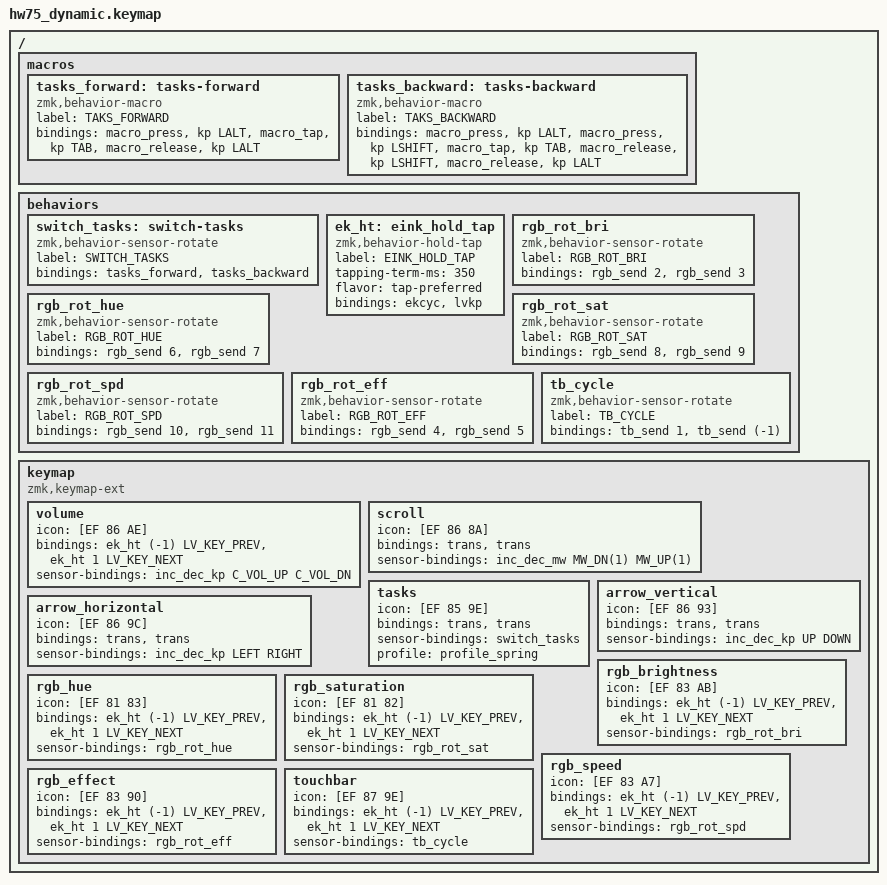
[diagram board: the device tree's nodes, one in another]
/*
 * Copyright (c) 2022 The ZMK Contributors
 * SPDX-License-Identifier: MIT
 */

#include <behaviors.dtsi>
#include <behaviors/lvgl_key_press.dtsi>
#include <behaviors/sensor_rotate_mouse_wheel.dtsi>
#include <behaviors/eink_mode_cycle.dtsi>
#include <behaviors/rgb_send.dtsi>
#include <behaviors/tb_send.dtsi>
#include <dt-bindings/zmk/keys.h>
#include <dt-bindings/zmk/rgb.h>
#include <dt-bindings/zmk/lvgl.h>
#include <dt-bindings/zmk/mouse.h>

/ {
	macros {
		tasks_forward: tasks-forward {
			label = "TAKS_FORWARD";
			compatible = "zmk,behavior-macro";
			#binding-cells = <0>;
			bindings = <&macro_press   &kp LALT>,
				   <&macro_tap     &kp TAB>,
				   <&macro_release &kp LALT>;
		};

		tasks_backward: tasks-backward {
			label = "TAKS_BACKWARD";
			compatible = "zmk,behavior-macro";
			#binding-cells = <0>;
			bindings = <&macro_press   &kp LALT>,
				   <&macro_press   &kp LSHIFT>,
				   <&macro_tap     &kp TAB>,
				   <&macro_release &kp LSHIFT>,
				   <&macro_release &kp LALT>;
		};
	};

	behaviors {
		switch_tasks: switch-tasks {
			compatible = "zmk,behavior-sensor-rotate";
			label = "SWITCH_TASKS";
			#sensor-binding-cells = <0>;
			bindings = <&tasks_forward>, <&tasks_backward>;
		};

		/*
		 * Short press -> LVGL keypad event (existing screen navigation).
		 * Long press  -> cycle E-Ink mode forward/backward.
		 * The two keymap cells are: <cycle-delta> <lvgl-key>.
		 */
		ek_ht: eink_hold_tap {
			compatible = "zmk,behavior-hold-tap";
			label = "EINK_HOLD_TAP";
			#binding-cells = <2>;
			tapping-term-ms = <350>;
			flavor = "tap-preferred";
			bindings = <&ekcyc>, <&lvkp>;
		};

		/*
		 * Knob -> keyboard underglow over D2K. Each rotate step sends one
		 * relative ±1 opcode (see uart_comm.proto RgbCmd). The keyboard is
		 * stateless; all the UI lives here on the dynamic module.
		 */
		rgb_rot_bri: rgb_rot_bri {
			compatible = "zmk,behavior-sensor-rotate";
			label = "RGB_ROT_BRI";
			#sensor-binding-cells = <0>;
			bindings = <&rgb_send 2>, <&rgb_send 3>;
		};
		rgb_rot_hue: rgb_rot_hue {
			compatible = "zmk,behavior-sensor-rotate";
			label = "RGB_ROT_HUE";
			#sensor-binding-cells = <0>;
			bindings = <&rgb_send 6>, <&rgb_send 7>;
		};
		rgb_rot_sat: rgb_rot_sat {
			compatible = "zmk,behavior-sensor-rotate";
			label = "RGB_ROT_SAT";
			#sensor-binding-cells = <0>;
			bindings = <&rgb_send 8>, <&rgb_send 9>;
		};
		rgb_rot_spd: rgb_rot_spd {
			compatible = "zmk,behavior-sensor-rotate";
			label = "RGB_ROT_SPD";
			#sensor-binding-cells = <0>;
			bindings = <&rgb_send 10>, <&rgb_send 11>;
		};
		rgb_rot_eff: rgb_rot_eff {
			compatible = "zmk,behavior-sensor-rotate";
			label = "RGB_ROT_EFF";
			#sensor-binding-cells = <0>;
			bindings = <&rgb_send 4>, <&rgb_send 5>;
		};

		/* Knob cycles the keyboard TouchBar mode (PAN/APP/DESKTOP) over D2K. */
		tb_cycle: tb_cycle {
			compatible = "zmk,behavior-sensor-rotate";
			label = "TB_CYCLE";
			#sensor-binding-cells = <0>;
			bindings = <&tb_send 1>, <&tb_send (-1)>;
		};
	};

	keymap {
		compatible = "zmk,keymap-ext", "zmk,keymap";

		volume {
			label = "音量";
			icon = [EF 86 AE];
			bindings = <&ek_ht (-1) LV_KEY_PREV &ek_ht 1 LV_KEY_NEXT>;
			sensor-bindings = <&inc_dec_kp C_VOL_UP C_VOL_DN>;
		};

		scroll {
			label = "滚动";
			icon = [EF 86 8A];
			bindings = <&trans &trans>;
			sensor-bindings = <&inc_dec_mw MW_DN(1) MW_UP(1)>;
		};

		tasks {
			label = "窗口";
			icon = [EF 85 9E];
			bindings = <&trans &trans>;
			sensor-bindings = <&switch_tasks>;
			profile = <&profile_spring>;
		};

		arrow_vertical {
			label = "上下";
			icon = [EF 86 93];
			bindings = <&trans &trans>;
			sensor-bindings = <&inc_dec_kp UP DOWN>;
		};

		arrow_horizontal {
			label = "左右";
			icon = [EF 86 9C];
			bindings = <&trans &trans>;
			sensor-bindings = <&inc_dec_kp LEFT RIGHT>;
		};

		/*
		 * On-device keyboard-RGB control. Knob rotation adjusts the parameter;
		 * the two keys navigate the carousel (short) / cycle E-Ink mode (long),
		 * same as the other layers. No PC needed.
		 */
		rgb_brightness {
			label = "亮度";
			icon = [EF 83 AB];
			bindings = <&ek_ht (-1) LV_KEY_PREV &ek_ht 1 LV_KEY_NEXT>;
			sensor-bindings = <&rgb_rot_bri>;
		};

		rgb_hue {
			label = "色相";
			icon = [EF 81 83];
			bindings = <&ek_ht (-1) LV_KEY_PREV &ek_ht 1 LV_KEY_NEXT>;
			sensor-bindings = <&rgb_rot_hue>;
		};

		rgb_saturation {
			label = "饱和";
			icon = [EF 81 82];
			bindings = <&ek_ht (-1) LV_KEY_PREV &ek_ht 1 LV_KEY_NEXT>;
			sensor-bindings = <&rgb_rot_sat>;
		};

		rgb_speed {
			label = "速度";
			icon = [EF 83 A7];
			bindings = <&ek_ht (-1) LV_KEY_PREV &ek_ht 1 LV_KEY_NEXT>;
			sensor-bindings = <&rgb_rot_spd>;
		};

		rgb_effect {
			label = "效果";
			icon = [EF 83 90];
			bindings = <&ek_ht (-1) LV_KEY_PREV &ek_ht 1 LV_KEY_NEXT>;
			sensor-bindings = <&rgb_rot_eff>;
		};

		touchbar {
			label = "触摸条";
			icon = [EF 87 9E];
			bindings = <&ek_ht (-1) LV_KEY_PREV &ek_ht 1 LV_KEY_NEXT>;
			sensor-bindings = <&tb_cycle>;
		};
	};
};
